AUTOSAR XML (schema 4-0-3)
standard types defined: boolean, float32, float64, sint16, sint32, sint8, uint16, uint32, uint8
package /ApplDataTypes
  app type ActionRequest: category=VALUE
  app type ButtonState: category=VALUE
  app type WindowPosition: category=VALUE
package /ImplDataTypes
  impl type ActionRequest: category=VALUE, base-type=boolean
  impl type ButtonState: category=VALUE, base-type=boolean
  impl type WindowPosition: category=VALUE, base-type=uint8
package /Interfaces
  sender receiver interface IfActionRequest
    data up: type=ActionRequest
    data down: type=ActionRequest
  client server interface IfButtonState
    operation GetButtonState
      arg up: type=ButtonState, direction=OUT
      arg down: type=ButtonState, direction=OUT
  client server interface IfWindowPosition
    operation SetWindowPosition
      arg position: type=WindowPosition, direction=IN
package /PowerWindowController
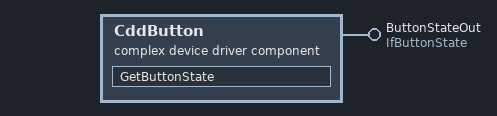
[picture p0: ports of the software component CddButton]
  complex device driver sw component type CddButton
    provide port ButtonStateOut: provided-interface=IfButtonState
    behavior IB_CB: data-type-mapping=PWC_DTM, handle-termination-and-restart=NO-SUPPORT
      operation invoked event OperationInvokedEvent: start-on-event=GetButtonState, operation=ButtonStateOut.GetButtonState
      runnable GetButtonState
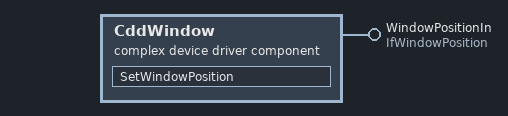
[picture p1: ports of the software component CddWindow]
  complex device driver sw component type CddWindow
    provide port WindowPositionIn: provided-interface=IfWindowPosition
    behavior IB_CW: data-type-mapping=PWC_DTM, handle-termination-and-restart=NO-SUPPORT
      operation invoked event OperationInvokedEvent: start-on-event=SetWindowPosition, operation=WindowPositionIn.SetWindowPosition
      runnable SetWindowPosition
  composition sw component type PWCTopLevel
    4 x component:
      CddButton: type=CddButton
      CddWindow: type=CddWindow
      PowerWindowController: type=PowerWindowController
      SensorButton: type=SensorButton
    connect CddButton.ButtonStateOut -> SensorButton.ButtonStateIn
    connect SensorButton.ActionRequestOut -> PowerWindowController.ActionRequestIn
    connect CddWindow.WindowPositionIn -> PowerWindowController.WindowPositionOut
  data type mapping set PWC_DTM
    data-type-maps:
      application-data-type=ActionRequest, implementation-data-type=ActionRequest
      application-data-type=ButtonState, implementation-data-type=ButtonState
      application-data-type=WindowPosition, implementation-data-type=WindowPosition
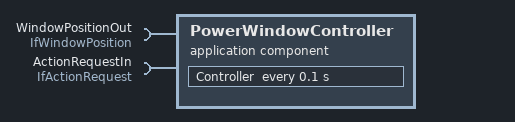
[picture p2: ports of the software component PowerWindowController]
  application sw component type PowerWindowController
    require port WindowPositionOut: required-interface=IfWindowPosition
    require port ActionRequestIn: required-interface=IfActionRequest
    behavior IB_PWC: data-type-mapping=PWC_DTM, handle-termination-and-restart=NO-SUPPORT
      timing event TimingEvent: start-on-event=Controller, period=0.1
      runnable Controller
        data-receive-point-by-arguments:
          access VariableAccess: accessed-variable=ActionRequestIn.up
          access VariableAccess1: accessed-variable=ActionRequestIn.down
        sync call SynchronousServerCallPoint: operation=WindowPositionOut.SetWindowPosition, timeout=0
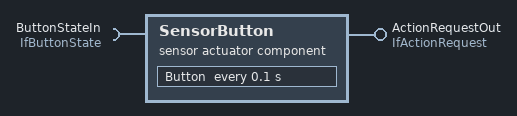
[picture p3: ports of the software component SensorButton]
  sensor actuator sw component type SensorButton: sensor-actuator=CddButton
    provide port ActionRequestOut: provided-interface=IfActionRequest
      provided-com-specs:
        data-element=down, transmission-acknowledge=timeout=0, init-value=TextValue:FALSE
        data-element=up, transmission-acknowledge=timeout=0, init-value=TextValue:FALSE
    require port ButtonStateIn: required-interface=IfButtonState
    behavior IB_SB: data-type-mapping=PWC_DTM, handle-termination-and-restart=NO-SUPPORT
      timing event TimingEvent: start-on-event=Button, period=0.1
      runnable Button
        data-send-points:
          access VariableAccess: accessed-variable=ActionRequestOut.up
          access VariableAccess1: accessed-variable=ActionRequestOut.down
        sync call SynchronousServerCallPoint: operation=ButtonStateIn.GetButtonState, timeout=0
package /System
  ecuc value collection EcucValueCollection: ecu-extract=SystemPWC, ecuc-values=[Os, Rte]
  system SystemPWC: system-version=1.0.0
    root-software-compositions:
      root sw composition prototype RootSwCompositionPrototype: software-composition=PWCTopLevel
